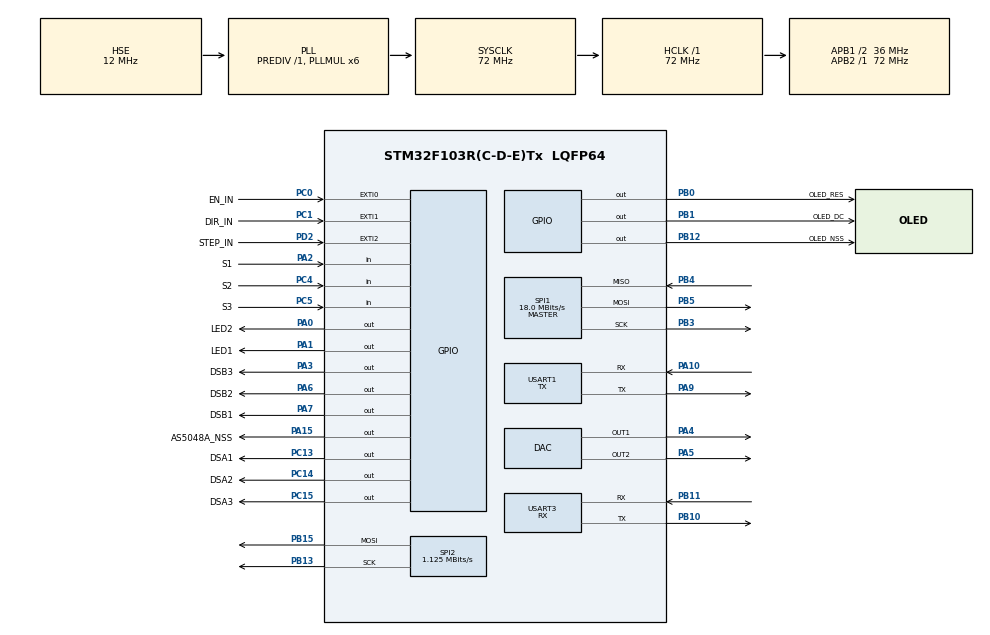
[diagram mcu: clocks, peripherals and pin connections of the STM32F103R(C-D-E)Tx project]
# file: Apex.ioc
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DAC.DAC_OutputBuffer=DAC_OUTPUTBUFFER_DISABLE
DAC.DAC_OutputBuffer2=DAC_OUTPUTBUFFER_DISABLE
Dma.Request0=SPI2_TX
Dma.Request1=USART1_TX
Dma.SPI2_TX.0.Direction=DMA_MEMORY_TO_PERIPH
Dma.SPI2_TX.0.Instance=DMA1_Channel5
Dma.SPI2_TX.0.MemDataAlignment=DMA_MDATAALIGN_BYTE
Dma.SPI2_TX.0.MemInc=DMA_MINC_ENABLE
Dma.SPI2_TX.0.Mode=DMA_NORMAL
Dma.SPI2_TX.0.PeriphDataAlignment=DMA_PDATAALIGN_BYTE
Dma.SPI2_TX.0.PeriphInc=DMA_PINC_DISABLE
Dma.SPI2_TX.0.Priority=DMA_PRIORITY_LOW
Dma.USART1_TX.1.Direction=DMA_MEMORY_TO_PERIPH
Dma.USART1_TX.1.Instance=DMA1_Channel4
Dma.USART1_TX.1.MemDataAlignment=DMA_MDATAALIGN_BYTE
Dma.USART1_TX.1.MemInc=DMA_MINC_ENABLE
Dma.USART1_TX.1.Mode=DMA_NORMAL
Dma.USART1_TX.1.PeriphDataAlignment=DMA_PDATAALIGN_BYTE
Dma.USART1_TX.1.PeriphInc=DMA_PINC_DISABLE
Dma.USART1_TX.1.Priority=DMA_PRIORITY_LOW
Mcu.Family=STM32F1
Mcu.Name=STM32F103R(C-D-E)Tx
Mcu.Package=LQFP64
NVIC.DMA1_Channel4_IRQn=true\:0\:0\:false\:false\:true\:false
NVIC.DMA1_Channel5_IRQn=true\:0\:0\:true\:false\:true\:false
NVIC.EXTI0_IRQn=true\:1\:0\:true\:false\:false\:true
NVIC.EXTI1_IRQn=true\:1\:0\:true\:false\:false\:true
NVIC.EXTI2_IRQn=true\:1\:0\:true\:false\:false\:true
NVIC.PriorityGroup=NVIC_PRIORITYGROUP_4
NVIC.TIM1_UP_IRQn=true\:2\:0\:true\:false\:false\:true
NVIC.USART1_IRQn=true\:3\:0\:true\:false\:true\:true
NVIC.USART3_IRQn=true\:3\:0\:true\:false\:true\:true
PA0-WKUP.GPIO_Label=LED2
PA0-WKUP.GPIO_ModeDefaultOutputPP=GPIO_MODE_OUTPUT_PP
PA0-WKUP.GPIO_Speed=GPIO_SPEED_FREQ_HIGH
PA0-WKUP.PinState=GPIO_PIN_SET
PA0-WKUP.Signal=GPIO_Output
PA1.GPIO_Label=LED1
PA1.GPIO_ModeDefaultOutputPP=GPIO_MODE_OUTPUT_PP
PA1.GPIO_Speed=GPIO_SPEED_FREQ_HIGH
PA1.PinState=GPIO_PIN_SET
PA1.Signal=GPIO_Output
PA10.GPIO_Mode=GPIO_MODE_INPUT
PA10.GPIO_PuPd=GPIO_PULLUP
PA10.Mode=Asynchronous
PA10.Signal=USART1_RX
PA13.Mode=Serial_Wire
PA13.Signal=SYS_JTMS-SWDIO
PA14.Mode=Serial_Wire
PA14.Signal=SYS_JTCK-SWCLK
PA15.GPIO_Label=AS5048A_NSS
PA15.GPIO_ModeDefaultOutputPP=GPIO_MODE_OUTPUT_PP
PA15.GPIO_Speed=GPIO_SPEED_FREQ_HIGH
PA15.PinState=GPIO_PIN_SET
PA15.Signal=GPIO_Output
PA2.GPIO_Label=S1
PA2.GPIO_Mode=GPIO_MODE_INPUT
PA2.GPIO_PuPd=GPIO_PULLUP
PA2.Signal=GPIO_Input
PA3.GPIO_Label=DSB3
PA3.GPIO_ModeDefaultOutputPP=GPIO_MODE_OUTPUT_PP
PA3.GPIO_Speed=GPIO_SPEED_FREQ_HIGH
PA3.PinState=GPIO_PIN_SET
PA3.Signal=GPIO_Output
PA4.Signal=COMP_DAC1_group
PA5.Signal=COMP_DAC2_group
PA6.GPIO_Label=DSB2
PA6.GPIO_ModeDefaultOutputPP=GPIO_MODE_OUTPUT_PP
PA6.GPIO_Speed=GPIO_SPEED_FREQ_HIGH
PA6.PinState=GPIO_PIN_SET
PA6.Signal=GPIO_Output
PA7.GPIO_Label=DSB1
PA7.GPIO_ModeDefaultOutputPP=GPIO_MODE_OUTPUT_PP
PA7.GPIO_Speed=GPIO_SPEED_FREQ_HIGH
PA7.PinState=GPIO_PIN_SET
PA7.Signal=GPIO_Output
PA9.Mode=Asynchronous
PA9.Signal=USART1_TX
PB0.GPIO_Label=OLED_RES
PB0.GPIO_ModeDefaultOutputPP=GPIO_MODE_OUTPUT_PP
PB0.GPIO_Speed=GPIO_SPEED_FREQ_HIGH
PB0.PinState=GPIO_PIN_SET
PB0.Signal=GPIO_Output
PB1.GPIO_Label=OLED_DC
PB1.GPIO_ModeDefaultOutputPP=GPIO_MODE_OUTPUT_PP
PB1.GPIO_Speed=GPIO_SPEED_FREQ_HIGH
PB1.PinState=GPIO_PIN_SET
PB1.Signal=GPIO_Output
PB10.Mode=Asynchronous
PB10.Signal=USART3_TX
PB11.GPIO_Mode=GPIO_MODE_INPUT
PB11.GPIO_PuPd=GPIO_PULLUP
PB11.Mode=Asynchronous
PB11.Signal=USART3_RX
PB12.GPIO_Label=OLED_NSS
PB12.GPIO_ModeDefaultOutputPP=GPIO_MODE_OUTPUT_PP
PB12.GPIO_Speed=GPIO_SPEED_FREQ_HIGH
PB12.PinState=GPIO_PIN_SET
PB12.Signal=GPIO_Output
PB13.Mode=TX_Only_Simplex_Unidirect_Master
PB13.Signal=SPI2_SCK
PB15.Mode=TX_Only_Simplex_Unidirect_Master
PB15.Signal=SPI2_MOSI
PB3.Mode=Full_Duplex_Master
PB3.Signal=SPI1_SCK
PB4.Mode=Full_Duplex_Master
PB4.Signal=SPI1_MISO
PB5.Mode=Full_Duplex_Master
PB5.Signal=SPI1_MOSI
PC0.GPIO_Label=EN_IN
PC0.GPIO_ModeDefaultEXTI=GPIO_MODE_IT_RISING_FALLING
PC0.GPIO_PuPd=GPIO_PULLUP
PC0.Signal=GPXTI0
PC1.GPIO_Label=DIR_IN
PC1.GPIO_ModeDefaultEXTI=GPIO_MODE_IT_RISING_FALLING
PC1.GPIO_PuPd=GPIO_PULLUP
PC1.Signal=GPXTI1
PC13-TAMPER-RTC.GPIO_Label=DSA1
PC13-TAMPER-RTC.GPIO_ModeDefaultOutputPP=GPIO_MODE_OUTPUT_PP
PC13-TAMPER-RTC.GPIO_Speed=GPIO_SPEED_FREQ_HIGH
PC13-TAMPER-RTC.PinState=GPIO_PIN_SET
PC13-TAMPER-RTC.Signal=GPIO_Output
PC14-OSC32_IN.GPIO_Label=DSA2
PC14-OSC32_IN.GPIO_ModeDefaultOutputPP=GPIO_MODE_OUTPUT_PP
PC14-OSC32_IN.GPIO_Speed=GPIO_SPEED_FREQ_HIGH
PC14-OSC32_IN.PinState=GPIO_PIN_SET
PC14-OSC32_IN.Signal=GPIO_Output
PC15-OSC32_OUT.GPIO_Label=DSA3
PC15-OSC32_OUT.GPIO_ModeDefaultOutputPP=GPIO_MODE_OUTPUT_PP
PC15-OSC32_OUT.GPIO_Speed=GPIO_SPEED_FREQ_HIGH
PC15-OSC32_OUT.PinState=GPIO_PIN_SET
PC15-OSC32_OUT.Signal=GPIO_Output
PC4.GPIO_Label=S2
PC4.GPIO_Mode=GPIO_MODE_INPUT
PC4.GPIO_PuPd=GPIO_PULLUP
PC4.Signal=GPIO_Input
PC5.GPIO_Label=S3
PC5.GPIO_Mode=GPIO_MODE_INPUT
PC5.GPIO_PuPd=GPIO_PULLUP
PC5.Signal=GPIO_Input
PD0-OSC_IN.Mode=HSE-External-Oscillator
PD0-OSC_IN.Signal=RCC_OSC_IN
PD1-OSC_OUT.Mode=HSE-External-Oscillator
PD1-OSC_OUT.Signal=RCC_OSC_OUT
PD2.GPIO_Label=STEP_IN
PD2.GPIO_ModeDefaultEXTI=GPIO_MODE_IT_RISING
PD2.GPIO_PuPd=GPIO_PULLUP
PD2.Signal=GPXTI2
ProjectManager.HeapSize=0x200
ProjectManager.StackSize=0x400
ProjectManager.TargetToolchain=MDK-ARM V5
RCC.AHBFreq_Value=72000000
RCC.APB1CLKDivider=RCC_HCLK_DIV2
RCC.APB1Freq_Value=36000000
RCC.APB1TimFreq_Value=72000000
RCC.APB2Freq_Value=72000000
RCC.APB2TimFreq_Value=72000000
RCC.HCLKFreq_Value=72000000
RCC.HSE_VALUE=12000000
RCC.PLLMUL=RCC_PLL_MUL6
RCC.PLLSourceVirtual=RCC_PLLSOURCE_HSE
RCC.SYSCLKFreq_VALUE=72000000
RCC.SYSCLKSource=RCC_SYSCLKSOURCE_PLLCLK
RCC.USBFreq_Value=72000000
SH.COMP_DAC1_group.0=DAC_OUT1,DAC_OUT1
SH.COMP_DAC2_group.0=DAC_OUT2,DAC_OUT2
SPI1.BaudRatePrescaler=SPI_BAUDRATEPRESCALER_4
SPI1.CLKPhase=SPI_PHASE_2EDGE
SPI1.CalculateBaudRate=18.0 MBits/s
SPI1.DataSize=SPI_DATASIZE_16BIT
SPI1.Direction=SPI_DIRECTION_2LINES
SPI1.Mode=SPI_MODE_MASTER
SPI1.VirtualType=VM_MASTER
SPI2.BaudRatePrescaler=SPI_BAUDRATEPRESCALER_32
SPI2.CLKPhase=SPI_PHASE_2EDGE
SPI2.CLKPolarity=SPI_POLARITY_HIGH
SPI2.CalculateBaudRate=1.125 MBits/s
SPI2.Direction=SPI_DIRECTION_2LINES
SPI2.Mode=SPI_MODE_MASTER
SPI2.VirtualType=VM_MASTER
TIM1.Period=100
TIM1.Prescaler=72
USART1.Mode=MODE_TX
USART1.VirtualMode=VM_ASYNC
USART3.Mode=MODE_RX
USART3.VirtualMode=VM_ASYNC
VP_TIM1_VS_ClockSourceINT.Mode=Internal
board=Apex

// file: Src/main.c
/**
  ******************************************************************************
  * @file           : main.c
  * @brief          : Main program body
  ******************************************************************************
  ** This notice applies to any and all portions of this file
  * that are not between comment pairs USER CODE BEGIN and
  * USER CODE END. Other portions of this file, whether
  * inserted by the user or by software development tools
  * are owned by their respective copyright owners.
  *
  * COPYRIGHT(c) 2018 STMicroelectronics
  *
  * Redistribution and use in source and binary forms, with or without modification,
  * are permitted provided that the following conditions are met:
  *   1. Redistributions of source code must retain the above copyright notice,
  *      this list of conditions and the following disclaimer.
  *   2. Redistributions in binary form must reproduce the above copyright notice,
  *      this list of conditions and the following disclaimer in the documentation
  *      and/or other materials provided with the distribution.
  *   3. Neither the name of STMicroelectronics nor the names of its contributors
  *      may be used to endorse or promote products derived from this software
  *      without specific prior written permission.
  *
  * THIS SOFTWARE IS PROVIDED BY THE COPYRIGHT HOLDERS AND CONTRIBUTORS "AS IS"
  * AND ANY EXPRESS OR IMPLIED WARRANTIES, INCLUDING, BUT NOT LIMITED TO, THE
  * IMPLIED WARRANTIES OF MERCHANTABILITY AND FITNESS FOR A PARTICULAR PURPOSE ARE
  * DISCLAIMED. IN NO EVENT SHALL THE COPYRIGHT HOLDER OR CONTRIBUTORS BE LIABLE
  * FOR ANY DIRECT, INDIRECT, INCIDENTAL, SPECIAL, EXEMPLARY, OR CONSEQUENTIAL
  * DAMAGES (INCLUDING, BUT NOT LIMITED TO, PROCUREMENT OF SUBSTITUTE GOODS OR
  * SERVICES; LOSS OF USE, DATA, OR PROFITS; OR BUSINESS INTERRUPTION) HOWEVER
  * CAUSED AND ON ANY THEORY OF LIABILITY, WHETHER IN CONTRACT, STRICT LIABILITY,
  * OR TORT (INCLUDING NEGLIGENCE OR OTHERWISE) ARISING IN ANY WAY OUT OF THE USE
  * OF THIS SOFTWARE, EVEN IF ADVISED OF THE POSSIBILITY OF SUCH DAMAGE.
  *
  ******************************************************************************
  */
#include "main.h"
#include "stm32f1xx_hal.h"

DAC_HandleTypeDef hdac;

SPI_HandleTypeDef hspi1;
SPI_HandleTypeDef hspi2;
DMA_HandleTypeDef hdma_spi2_tx;

TIM_HandleTypeDef htim1;

UART_HandleTypeDef huart1;
UART_HandleTypeDef huart3;
DMA_HandleTypeDef hdma_usart1_tx;

/* USER CODE BEGIN PV */
/* Private variables ---------------------------------------------------------*/

/* USER CODE END PV */

void SystemClock_Config(void);
static void MX_GPIO_Init(void);
static void MX_DMA_Init(void);
static void MX_DAC_Init(void);
static void MX_USART1_UART_Init(void);
static void MX_USART3_UART_Init(void);
static void MX_SPI2_Init(void);
static void MX_SPI1_Init(void);
static void MX_TIM1_Init(void);

/* USER CODE BEGIN PFP */
/* Private function prototypes -----------------------------------------------*/

/* USER CODE END PFP */

/* USER CODE BEGIN 0 */
#include "loop.h"
/* USER CODE END 0 */

int main(void)
{

  /* MCU Configuration----------------------------------------------------------*/

  /* Reset of all peripherals, Initializes the Flash interface and the Systick. */
  HAL_Init();

  /* Configure the system clock */
  SystemClock_Config();

  /* Initialize all configured peripherals */
  MX_GPIO_Init();
  MX_DMA_Init();
  MX_DAC_Init();
  MX_USART1_UART_Init();
  MX_USART3_UART_Init();
  MX_SPI2_Init();
  MX_SPI1_Init();
  MX_TIM1_Init();
  /* USER CODE BEGIN 2 */
  loop();
  /* USER CODE END 2 */

  /* Infinite loop */
  while (1)
  {

  }

}

void SystemClock_Config(void)
{

  RCC_OscInitTypeDef RCC_OscInitStruct;
  RCC_ClkInitTypeDef RCC_ClkInitStruct;

    /**Initializes the CPU, AHB and APB busses clocks
    */
  RCC_OscInitStruct.OscillatorType = RCC_OSCILLATORTYPE_HSE;
  RCC_OscInitStruct.HSEState = RCC_HSE_ON;
  RCC_OscInitStruct.HSEPredivValue = RCC_HSE_PREDIV_DIV1;
  RCC_OscInitStruct.HSIState = RCC_HSI_ON;
  RCC_OscInitStruct.PLL.PLLState = RCC_PLL_ON;
  RCC_OscInitStruct.PLL.PLLSource = RCC_PLLSOURCE_HSE;
  RCC_OscInitStruct.PLL.PLLMUL = RCC_PLL_MUL6;
  if (HAL_RCC_OscConfig(&RCC_OscInitStruct) != HAL_OK)
  {
    _Error_Handler(__FILE__, __LINE__);
  }

    /**Initializes the CPU, AHB and APB busses clocks
    */
  RCC_ClkInitStruct.ClockType = RCC_CLOCKTYPE_HCLK|RCC_CLOCKTYPE_SYSCLK
                              |RCC_CLOCKTYPE_PCLK1|RCC_CLOCKTYPE_PCLK2;
  RCC_ClkInitStruct.SYSCLKSource = RCC_SYSCLKSOURCE_PLLCLK;
  RCC_ClkInitStruct.AHBCLKDivider = RCC_SYSCLK_DIV1;
  RCC_ClkInitStruct.APB1CLKDivider = RCC_HCLK_DIV2;
  RCC_ClkInitStruct.APB2CLKDivider = RCC_HCLK_DIV1;

  if (HAL_RCC_ClockConfig(&RCC_ClkInitStruct, FLASH_LATENCY_2) != HAL_OK)
  {
    _Error_Handler(__FILE__, __LINE__);
  }

    /**Configure the Systick interrupt time
    */
  HAL_SYSTICK_Config(HAL_RCC_GetHCLKFreq()/1000);

    /**Configure the Systick
    */
  HAL_SYSTICK_CLKSourceConfig(SYSTICK_CLKSOURCE_HCLK);

  /* SysTick_IRQn interrupt configuration */
  HAL_NVIC_SetPriority(SysTick_IRQn, 0, 0);
}

/* DAC init function */
static void MX_DAC_Init(void)
{

  DAC_ChannelConfTypeDef sConfig;

    /**DAC Initialization
    */
  hdac.Instance = DAC;
  if (HAL_DAC_Init(&hdac) != HAL_OK)
  {
    _Error_Handler(__FILE__, __LINE__);
  }

    /**DAC channel OUT1 config
    */
  sConfig.DAC_Trigger = DAC_TRIGGER_NONE;
  sConfig.DAC_OutputBuffer = DAC_OUTPUTBUFFER_DISABLE;
  if (HAL_DAC_ConfigChannel(&hdac, &sConfig, DAC_CHANNEL_1) != HAL_OK)
  {
    _Error_Handler(__FILE__, __LINE__);
  }

    /**DAC channel OUT2 config
    */
  if (HAL_DAC_ConfigChannel(&hdac, &sConfig, DAC_CHANNEL_2) != HAL_OK)
  {
    _Error_Handler(__FILE__, __LINE__);
  }

}

/* SPI1 init function */
static void MX_SPI1_Init(void)
{

  /* SPI1 parameter configuration*/
  hspi1.Instance = SPI1;
  hspi1.Init.Mode = SPI_MODE_MASTER;
  hspi1.Init.Direction = SPI_DIRECTION_2LINES;
  hspi1.Init.DataSize = SPI_DATASIZE_16BIT;
  hspi1.Init.CLKPolarity = SPI_POLARITY_LOW;
  hspi1.Init.CLKPhase = SPI_PHASE_2EDGE;
  hspi1.Init.NSS = SPI_NSS_SOFT;
  hspi1.Init.BaudRatePrescaler = SPI_BAUDRATEPRESCALER_4;
  hspi1.Init.FirstBit = SPI_FIRSTBIT_MSB;
  hspi1.Init.TIMode = SPI_TIMODE_DISABLE;
  hspi1.Init.CRCCalculation = SPI_CRCCALCULATION_DISABLE;
  hspi1.Init.CRCPolynomial = 10;
  if (HAL_SPI_Init(&hspi1) != HAL_OK)
  {
    _Error_Handler(__FILE__, __LINE__);
  }

}

/* SPI2 init function */
static void MX_SPI2_Init(void)
{

  /* SPI2 parameter configuration*/
  hspi2.Instance = SPI2;
  hspi2.Init.Mode = SPI_MODE_MASTER;
  hspi2.Init.Direction = SPI_DIRECTION_2LINES;
  hspi2.Init.DataSize = SPI_DATASIZE_8BIT;
  hspi2.Init.CLKPolarity = SPI_POLARITY_HIGH;
  hspi2.Init.CLKPhase = SPI_PHASE_2EDGE;
  hspi2.Init.NSS = SPI_NSS_SOFT;
  hspi2.Init.BaudRatePrescaler = SPI_BAUDRATEPRESCALER_32;
  hspi2.Init.FirstBit = SPI_FIRSTBIT_MSB;
  hspi2.Init.TIMode = SPI_TIMODE_DISABLE;
  hspi2.Init.CRCCalculation = SPI_CRCCALCULATION_DISABLE;
  hspi2.Init.CRCPolynomial = 10;
  if (HAL_SPI_Init(&hspi2) != HAL_OK)
  {
    _Error_Handler(__FILE__, __LINE__);
  }

}

/* TIM1 init function */
static void MX_TIM1_Init(void)
{

  TIM_ClockConfigTypeDef sClockSourceConfig;
  TIM_MasterConfigTypeDef sMasterConfig;

  htim1.Instance = TIM1;
  htim1.Init.Prescaler = 72;
  htim1.Init.CounterMode = TIM_COUNTERMODE_UP;
  htim1.Init.Period = 100;
  htim1.Init.ClockDivision = TIM_CLOCKDIVISION_DIV1;
  htim1.Init.RepetitionCounter = 0;
  htim1.Init.AutoReloadPreload = TIM_AUTORELOAD_PRELOAD_DISABLE;
  if (HAL_TIM_Base_Init(&htim1) != HAL_OK)
  {
    _Error_Handler(__FILE__, __LINE__);
  }

  sClockSourceConfig.ClockSource = TIM_CLOCKSOURCE_INTERNAL;
  if (HAL_TIM_ConfigClockSource(&htim1, &sClockSourceConfig) != HAL_OK)
  {
    _Error_Handler(__FILE__, __LINE__);
  }

  sMasterConfig.MasterOutputTrigger = TIM_TRGO_RESET;
  sMasterConfig.MasterSlaveMode = TIM_MASTERSLAVEMODE_DISABLE;
  if (HAL_TIMEx_MasterConfigSynchronization(&htim1, &sMasterConfig) != HAL_OK)
  {
    _Error_Handler(__FILE__, __LINE__);
  }

}

/* USART1 init function */
static void MX_USART1_UART_Init(void)
{

  huart1.Instance = USART1;
  huart1.Init.BaudRate = 115200;
  huart1.Init.WordLength = UART_WORDLENGTH_8B;
  huart1.Init.StopBits = UART_STOPBITS_1;
  huart1.Init.Parity = UART_PARITY_NONE;
  huart1.Init.Mode = UART_MODE_TX;
  huart1.Init.HwFlowCtl = UART_HWCONTROL_NONE;
  huart1.Init.OverSampling = UART_OVERSAMPLING_16;
  if (HAL_UART_Init(&huart1) != HAL_OK)
  {
    _Error_Handler(__FILE__, __LINE__);
  }

}

/* USART3 init function */
static void MX_USART3_UART_Init(void)
{

  huart3.Instance = USART3;
  huart3.Init.BaudRate = 115200;
  huart3.Init.WordLength = UART_WORDLENGTH_8B;
  huart3.Init.StopBits = UART_STOPBITS_1;
  huart3.Init.Parity = UART_PARITY_NONE;
  huart3.Init.Mode = UART_MODE_RX;
  huart3.Init.HwFlowCtl = UART_HWCONTROL_NONE;
  huart3.Init.OverSampling = UART_OVERSAMPLING_16;
  if (HAL_UART_Init(&huart3) != HAL_OK)
  {
    _Error_Handler(__FILE__, __LINE__);
  }

}

static void MX_DMA_Init(void)
{
  /* DMA controller clock enable */
  __HAL_RCC_DMA1_CLK_ENABLE();

  /* DMA interrupt init */
  /* DMA1_Channel4_IRQn interrupt configuration */
  HAL_NVIC_SetPriority(DMA1_Channel4_IRQn, 0, 0);
  HAL_NVIC_EnableIRQ(DMA1_Channel4_IRQn);
  /* DMA1_Channel5_IRQn interrupt configuration */
  HAL_NVIC_SetPriority(DMA1_Channel5_IRQn, 0, 0);
  HAL_NVIC_EnableIRQ(DMA1_Channel5_IRQn);

}

/** Configure pins as
        * Analog
        * Input
        * Output
        * EVENT_OUT
        * EXTI
*/
static void MX_GPIO_Init(void)
{

  GPIO_InitTypeDef GPIO_InitStruct;

  /* GPIO Ports Clock Enable */
  __HAL_RCC_GPIOC_CLK_ENABLE();
  __HAL_RCC_GPIOD_CLK_ENABLE();
  __HAL_RCC_GPIOA_CLK_ENABLE();
  __HAL_RCC_GPIOB_CLK_ENABLE();

  /*Configure GPIO pin Output Level */
  HAL_GPIO_WritePin(GPIOC, DSA1_Pin|DSA2_Pin|DSA3_Pin, GPIO_PIN_SET);

  /*Configure GPIO pin Output Level */
  HAL_GPIO_WritePin(GPIOA, LED2_Pin|LED1_Pin|DSB3_Pin|DSB2_Pin
                          |DSB1_Pin|AS5048A_NSS_Pin, GPIO_PIN_SET);

  /*Configure GPIO pin Output Level */
  HAL_GPIO_WritePin(GPIOB, OLED_RES_Pin|OLED_DC_Pin|OLED_NSS_Pin, GPIO_PIN_SET);

  /*Configure GPIO pins : DSA1_Pin DSA2_Pin DSA3_Pin */
  GPIO_InitStruct.Pin = DSA1_Pin|DSA2_Pin|DSA3_Pin;
  GPIO_InitStruct.Mode = GPIO_MODE_OUTPUT_PP;
  GPIO_InitStruct.Speed = GPIO_SPEED_FREQ_HIGH;
  HAL_GPIO_Init(GPIOC, &GPIO_InitStruct);

  /*Configure GPIO pins : EN_IN_Pin DIR_IN_Pin */
  GPIO_InitStruct.Pin = EN_IN_Pin|DIR_IN_Pin;
  GPIO_InitStruct.Mode = GPIO_MODE_IT_RISING_FALLING;
  GPIO_InitStruct.Pull = GPIO_PULLUP;
  HAL_GPIO_Init(GPIOC, &GPIO_InitStruct);

  /*Configure GPIO pins : LED2_Pin LED1_Pin DSB3_Pin DSB2_Pin
                           DSB1_Pin AS5048A_NSS_Pin */
  GPIO_InitStruct.Pin = LED2_Pin|LED1_Pin|DSB3_Pin|DSB2_Pin
                          |DSB1_Pin|AS5048A_NSS_Pin;
  GPIO_InitStruct.Mode = GPIO_MODE_OUTPUT_PP;
  GPIO_InitStruct.Speed = GPIO_SPEED_FREQ_HIGH;
  HAL_GPIO_Init(GPIOA, &GPIO_InitStruct);

  /*Configure GPIO pin : S1_Pin */
  GPIO_InitStruct.Pin = S1_Pin;
  GPIO_InitStruct.Mode = GPIO_MODE_INPUT;
  GPIO_InitStruct.Pull = GPIO_PULLUP;
  HAL_GPIO_Init(S1_GPIO_Port, &GPIO_InitStruct);

  /*Configure GPIO pins : S2_Pin S3_Pin */
  GPIO_InitStruct.Pin = S2_Pin|S3_Pin;
  GPIO_InitStruct.Mode = GPIO_MODE_INPUT;
  GPIO_InitStruct.Pull = GPIO_PULLUP;
  HAL_GPIO_Init(GPIOC, &GPIO_InitStruct);

  /*Configure GPIO pins : OLED_RES_Pin OLED_DC_Pin OLED_NSS_Pin */
  GPIO_InitStruct.Pin = OLED_RES_Pin|OLED_DC_Pin|OLED_NSS_Pin;
  GPIO_InitStruct.Mode = GPIO_MODE_OUTPUT_PP;
  GPIO_InitStruct.Speed = GPIO_SPEED_FREQ_HIGH;
  HAL_GPIO_Init(GPIOB, &GPIO_InitStruct);

  /*Configure GPIO pin : STEP_IN_Pin */
  GPIO_InitStruct.Pin = STEP_IN_Pin;
  GPIO_InitStruct.Mode = GPIO_MODE_IT_RISING;
  GPIO_InitStruct.Pull = GPIO_PULLUP;
  HAL_GPIO_Init(STEP_IN_GPIO_Port, &GPIO_InitStruct);

  /* EXTI interrupt init*/
  HAL_NVIC_SetPriority(EXTI0_IRQn, 1, 0);
  HAL_NVIC_EnableIRQ(EXTI0_IRQn);

  HAL_NVIC_SetPriority(EXTI1_IRQn, 1, 0);
  HAL_NVIC_EnableIRQ(EXTI1_IRQn);

  HAL_NVIC_SetPriority(EXTI2_IRQn, 1, 0);
  HAL_NVIC_EnableIRQ(EXTI2_IRQn);

}

void _Error_Handler(char *file, int line)
{
  while(1)
  {
  }
}

/************************ (C) COPYRIGHT STMicroelectronics *****END OF FILE****/
